# ET6801 register map
Vendor: ETMCU Inc.; File version: v0.0.1
CPU: CM7 r2p1, little endian, MPU, FPU, I-cache, D-cache, ITCM, DTCM, 4 interrupt priority bits
Registers are 32-bit, read-write, reset 0x0 unless marked. A register's access mark holds for its fields unless they carry their own. Offsets are from the block's base; [hi:lo] are bit positions; {n}, {i} and the like mark numbered series.

## SRPWMCOM — Provide an overview of the purpose and functionality of the peripheral: epwmcom_cfg
Base 0x40000000
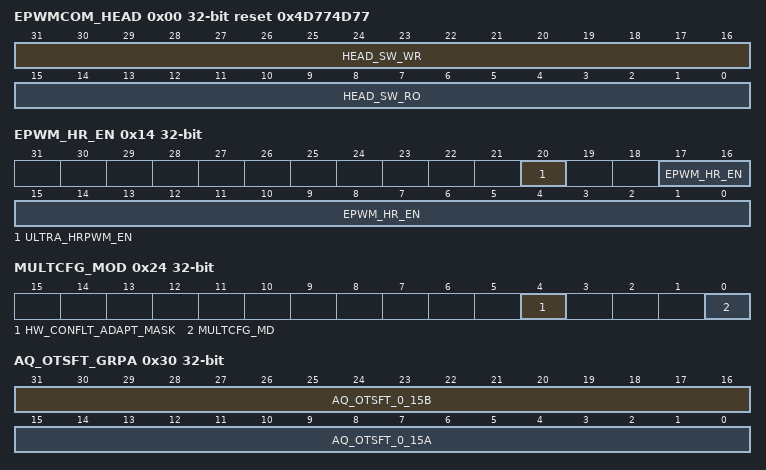
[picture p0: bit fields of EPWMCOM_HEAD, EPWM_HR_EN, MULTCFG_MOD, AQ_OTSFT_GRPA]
0x00 EPWMCOM_HEAD reset 0x4D774D77
  [31:16] HEAD_SW_WR — 软件测试读写寄存器，硬件无访问
  [15:0] HEAD_SW_RO ro — 软件只读上报寄存器，硬件无访问,XXX的ASICII 码表示
0x10 EPWM_EN
  [17:0] EPWM_EN — EPWM模块使能信号，每个EPWM模块对应1bit；bit0~bit11分别对应EPWM0~18； 0：不使能； 1：使能。
0x14 EPWM_HR_EN
  [20] ULTRA_HRPWM_EN — 超高精度PWM模式使能。 'b0：支持分辨率为156.25ps的高精度PWM 'b1：支持分辨率为78.125ps的超高精度PWM
  [17:0] EPWM_HR_EN — EPWM模块高精度发波使能信号，每个EPWM模块对应1bit；bit0~bit11分别对应EPWM0~11； 0：不使能； 1：使能。
0x20 SHD_MULTICFG_UPT
  [17:0] SHD_MULTICFG_UPT — 多个EPWM模块配置寄存器同步更新，写1产生脉冲进行更新；每一bit对应一个epwm模块，bit0~bit18分别对应EPWM0~18；
0x24 MULTCFG_MOD
  [4] HW_CONFLT_ADAPT_MASK — b0：做同步加载的冲突规避 'b1：不做同步加载的冲突规避
  [0] MULTCFG_MD — 同步加载冲突规避模式选择寄存器 1'b0：发生冲突时配置寄存器优先，在软件对参与通道间同步加载的寄存器写配置参数期间，不产生影子加载事件更新活跃值的动作，直至软件完成相关寄存器配置并对寄存器CFG_SHD_MULTICFG_UPT进行写操作后才恢复对影子事件的等待和响应； 1'b1：发生冲突时影子加载事件优先，在影子事件出现之前的一定时间范围内（用户配置时间范围长度），软件写下来的配置不会写到寄存器中。
0x28 MULTCFG_FB_ZONE
  [13:0] MULTCFG_FB_ZONE — 同步加载参数禁止写入区间寄存器，用于指定影子事件出现之前不对（参与通道间同步加载的）寄存器进行更新的时间范围，以SRPWM模块的工作时钟周期为单位，当工作时钟为200MHz时，最大值对应82us左右时间。需注意此寄存器的配置值应小于通道内寄存器CFG_TB_PRD[cfg_tb_prd[28:7]]的配置值。此寄存器配置值仅在CFG_MULT_CFG_MD='b1时才有意义。
0x2C MULTCFG_CONFLICT_RPT ro
  [17:0] MULTCFG_CONFLICT_RPT — 上报同步加载期间的冲突事件。每个比特对应一个PWM通道，LSB对应PWM0通道，MSB对应PWM17通道，高电平表示出现过冲突，置高电平后保持，需要软件通过对寄存器cfg_multcfg_conflict_rpt_clr对应比特写1清除。 当CFG_ MULT_CFG_MD配置为'b0，在某个通道内，从出现第一个同步加载参数的写使能到同步加载指令脉冲（寄存器CFG_SHD_MULTICFG_UPT写1产生的脉冲）出现之前的时间段内如果出现该通道的同步加载影子事件（此时间段内出现的影子事件实际未起作用，未进行活跃值更新），则该通道对应的multcfg_conflict_rpt寄存器比特将被置1。 当CFG_ MULT_CFG_MD配置为'b1，在某个通道内，影子事件出现前的禁止写寄存器时间段内（由寄存器CFG_MULT_CFG_FB_ZONE指定），如果发生软件对同步加载相关寄存器的写操作，则该通道对应的multcfg_conflict_rpt寄存器比特将被置1。
0x30 AQ_OTSFT_GRPA
  [31:16] AQ_OTSFT_0_15B — epwmb信号软件触发一次(one time)强制动作，写1产生脉冲。 bit0~bit11分别对应EPWM0~15； 此寄存器是写自清零寄存器，软件写一次1产生一个脉冲，软件配置1后，对应通道的AQ逻辑响应此脉冲，等到寄存器cfg_aq_sftstart_sync_mselb选定的start事件有效，会执行动作（动作内容由AQ寄存器cfg_aq_ctl_sftb决定），然后等AQ寄存器cfg_aq_sftend_sync_mselb选定的end事件有效，该次软件强制动作结束。由于软件写一次只产生一个脉冲，因此动作持续的时间是从 start事件到end事件的间隔时间。软件配置动作的优先级高于AQ矩阵的其余22个事件。
  [15:0] AQ_OTSFT_0_15A — epwma信号软件触发一次(one time)强制动作，写1产生脉冲。 bit0~bit11分别对应EPWM0~15； 此寄存器是写自清零寄存器，软件写一次1产生一个脉冲，软件配置1后，对应通道的AQ逻辑响应此脉冲，等到寄存器cfg_aq_sftstart_sync_msela选定的start事件有效，会执行动作（动作内容由AQ寄存器cfg_aq_ctl_sfta决定），然后等AQ寄存器cfg_aq_sftend_sync_msela选定的end事件有效，该次软件强制动作结束。由于软件写一次只产生一个脉冲，因此动作持续的时间是从 start事件到end事件的间隔时间。软件配置动作的优先级高于AQ矩阵的其余22个事件。
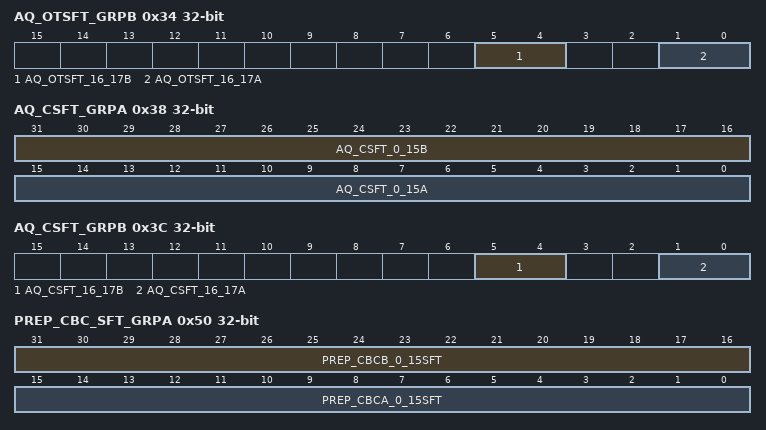
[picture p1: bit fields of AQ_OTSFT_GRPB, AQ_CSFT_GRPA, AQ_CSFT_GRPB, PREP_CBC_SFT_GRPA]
0x34 AQ_OTSFT_GRPB
  [5:4] AQ_OTSFT_16_17B — epwmb信号软件触发一次(one time)强制动作，写1产生脉冲。 bit0~bit1分别对应EPWM16~17； 此寄存器是写自清零寄存器，软件写一次1产生一个脉冲，软件配置1后，对应通道的AQ逻辑响应此脉冲，等到寄存器cfg_aq_sftstart_sync_mselb选定的start事件有效，会执行动作（动作内容由AQ寄存器cfg_aq_ctl_sftb决定），然后等AQ寄存器cfg_aq_sftend_sync_mselb选定的end事件有效，该次软件强制动作结束。由于软件写一次只产生一个脉冲，因此动作持续的时间是从 start事件到end事件的间隔时间。软件配置动作的优先级高于AQ矩阵的其余22个事件。
  [1:0] AQ_OTSFT_16_17A — epwma信号软件触发一次(one time)强制动作，写1产生脉冲。 bit0~bit1分别对应EPWM16~17； 此寄存器是写自清零寄存器，软件写一次1产生一个脉冲，软件配置1后，对应通道的AQ逻辑响应此脉冲，等到寄存器cfg_aq_sftstart_sync_msela选定的start事件有效，会执行动作（动作内容由AQ寄存器cfg_aq_ctl_sfta决定），然后等AQ寄存器cfg_aq_sftend_sync_msela选定的end事件有效，该次软件强制动作结束。由于软件写一次只产生一个脉冲，因此动作持续的时间是从 start事件到end事件的间隔时间。软件配置动作的优先级高于AQ矩阵的其余22个事件。
0x38 AQ_CSFT_GRPA
  [31:16] AQ_CSFT_0_15B — epwmb信号软件持续(continuous)强制动作。配置为1生效，配置0退出。 bit0~bit15分别对应EPWM0~15； 与cfg_aq_otsftb寄存器不同，此寄存器是写1后持续保持高电平，软件配置1后，根据AQ寄存器cfg_aq_sftstart_mdb的配置值不同，会立即产生动作或者是等到寄存器cfg_aq_sftstart_sync_mselb选定的start事件有效再执行动作（动作内容由AQ寄存器cfg_aq_ctl_sftb决定），当前寄存器从置1变为置0后，根据AQ寄存器cfg_aq_sftend_mdb的配置值不同，动作立即结束或等AQ寄存器cfg_aq_sftend_sync_mselb选定的end事件有效，该次软件强制动作结束。软件配置动作的优先级高于AQ矩阵的其余22个事件。
  [15:0] AQ_CSFT_0_15A — epwma信号软件持续(continuous)强制动作。配置为1生效，配置0退出。 bit0~bit15分别对应EPWM0~15； 与cfg_aq_otsfta寄存器不同，此寄存器是写1后持续保持高电平，软件配置1后，根据AQ寄存器cfg_aq_sftstart_mda的配置值不同，会立即产生动作或者是等到寄存器cfg_aq_sftstart_sync_msela选定的start事件有效再执行动作（动作内容由AQ寄存器cfg_aq_ctl_sfta决定），当前寄存器从置1变为置0后，根据AQ寄存器cfg_aq_sftend_mda的配置值不同，动作立即结束或等AQ寄存器cfg_aq_sftend_sync_msela选定的end事件有效，该次软件强制动作结束。软件配置动作的优先级高于AQ矩阵的其余22个事件。
0x3C AQ_CSFT_GRPB
  [5:4] AQ_CSFT_16_17B — epwmb信号软件持续(continuous)强制动作。配置为1生效，配置0退出。 bit0~bit1分别对应EPWM16~17； 与cfg_aq_otsftb寄存器不同，此寄存器是写1后持续保持高电平，软件配置1后，根据AQ寄存器cfg_aq_sftstart_mdb的配置值不同，会立即产生动作或者是等到寄存器cfg_aq_sftstart_sync_mselb选定的start事件有效再执行动作（动作内容由AQ寄存器cfg_aq_ctl_sftb决定），当前寄存器从置1变为置0后，根据AQ寄存器cfg_aq_sftend_mdb的配置值不同，动作立即结束或等AQ寄存器cfg_aq_sftend_sync_mselb选定的end事件有效，该次软件强制动作结束。软件配置动作的优先级高于AQ矩阵的其余22个事件。
  [1:0] AQ_CSFT_16_17A — epwma信号软件持续(continuous)强制动作。配置为1生效，配置0退出。 bit0~bit1分别对应EPWM16~17； 与cfg_aq_otsfta寄存器不同，此寄存器是写1后持续保持高电平，软件配置1后，根据AQ寄存器cfg_aq_sftstart_mda的配置值不同，会立即产生动作或者是等到寄存器cfg_aq_sftstart_sync_msela选定的start事件有效再执行动作（动作内容由AQ寄存器cfg_aq_ctl_sfta决定），当前寄存器从置1变为置0后，根据AQ寄存器cfg_aq_sftend_mda的配置值不同，动作立即结束或等AQ寄存器cfg_aq_sftend_sync_msela选定的end事件有效，该次软件强制动作结束。软件配置动作的优先级高于AQ矩阵的其余22个事件。
0x40 EPWM_SFT_EVT
  [17:0] EPWM_SFT_EVT — 软件事件，通过软件写1产生脉冲，得到对应的事件；用于各种同步信号选择； bit0~bit17分别对应EPWM0~17；
0x44 MULTCFG_CONFLT_CLR
  [17:0] MULTCFG_CONFLICT_RPT_CLR — 软件事件，通过软件写1产生脉冲，得到对应的事件；用于一一对应清除cfg_multcfg_conflict_rpt寄存器； bit0~bit17分别对应EPWM0~17；
0x50 PREP_CBC_SFT_GRPA
  [31:16] PREP_CBCB_0_15SFT — 软件配置触发epwmb产生CBC保护，写1产生脉冲。 bit0~bit15分别对应EPWM0~15；
  [15:0] PREP_CBCA_0_15SFT — 软件配置触发epwma产生CBC保护，写1产生脉冲。 bit0~bit15分别对应EPWM0~15；
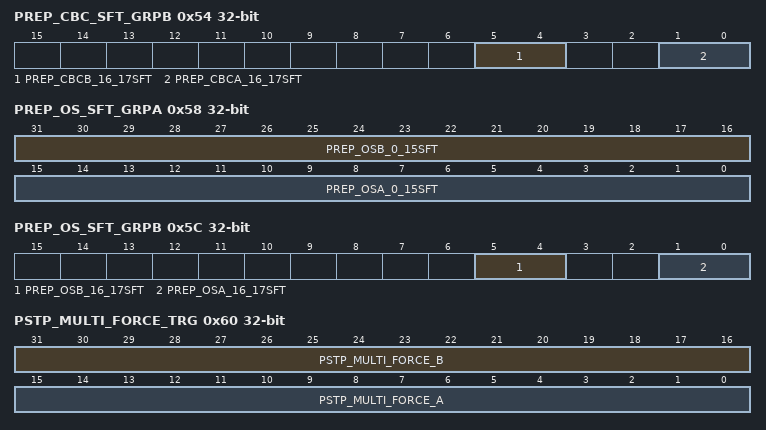
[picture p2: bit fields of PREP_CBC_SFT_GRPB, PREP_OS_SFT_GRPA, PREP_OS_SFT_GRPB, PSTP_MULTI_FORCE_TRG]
0x54 PREP_CBC_SFT_GRPB
  [5:4] PREP_CBCB_16_17SFT — 软件配置触发epwmb产生CBC保护，写1产生脉冲。 bit0~bit1分别对应EPWM16~17；
  [1:0] PREP_CBCA_16_17SFT — 软件配置触发epwma产生CBC保护，写1产生脉冲。 bit0~bit1分别对应EPWM16~17；
0x58 PREP_OS_SFT_GRPA
  [31:16] PREP_OSB_0_15SFT — 软件配置触发epwmb产生one shot保护，软件配置产生电平。 bit0~bit11分别对应EPWM0~11；
  [15:0] PREP_OSA_0_15SFT — 软件配置触发epwma产生one shot保护，软件配置产生电平。 bit0~bit11分别对应EPWM0~11；
0x5C PREP_OS_SFT_GRPB
  [5:4] PREP_OSB_16_17SFT — 软件配置触发epwmb产生one shot保护，软件配置产生电平。 bit0~bit1分别对应EPWM16~17；
  [1:0] PREP_OSA_16_17SFT — 软件配置触发epwma产生one shot保护，软件配置产生电平。 bit0~bit1分别对应EPWM16~17；
0x60 PSTP_MULTI_FORCE_TRG
  [31:16] PSTP_MULTI_FORCE_B — 写1产生触发脉冲，软件配置触发pwmb产生强制次级保护动作， bit0~bit15分别对应SRPWMB0~15。此触发动作仅在通道内寄存器CFG_PSTP_SFT_FORCE[cfg_pstp_glb_force_en]='b1时有效（每个PWM通道独立配置），具体强制动作结果由通道内寄存器CFG_PSTP_SFT_FORCE配置。
  [15:0] PSTP_MULTI_FORCE_A — 写1产生触发脉冲，软件配置触发pwma产生强制次级保护动作， bit0~bit15分别对应SRPWMA0~15。此触发动作仅在通道内寄存器CFG_PSTP_SFT_FORCE[cfg_pstp_glb_force_en]='b1时有效（每个PWM通道独立配置），具体强制动作结果由通道内寄存器CFG_PSTP_SFT_FORCE配置。
0x64 PSTP_MCHAN_FORCE_TRG
  [17:0] PSTP_MCHAN_FORCE_TRG — 写1产生触发脉冲，软件配置触发pwm通道的a、b支路产生强制次级保护动作， bit0~bit17分别对应SRPWM0~17。此触发动作仅在通道内寄存器CFG_PSTP_SFT_FORCE[cfg_pstp_glb_force_en]='b1时有效（每个PWM通道独立配置），具体强制动作结果由通道内寄存器CFG_PSTP_SFT_FORCE配置。
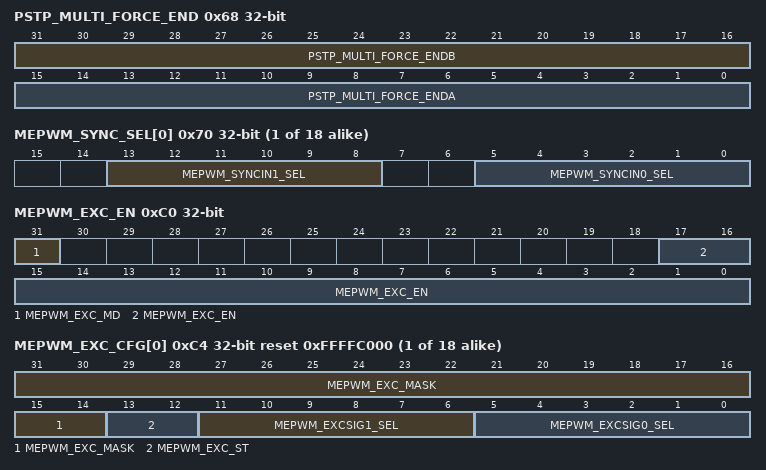
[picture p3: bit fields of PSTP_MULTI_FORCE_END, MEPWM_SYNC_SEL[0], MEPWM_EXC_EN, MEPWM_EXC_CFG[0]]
0x68 PSTP_MULTI_FORCE_END
  [31:16] PSTP_MULTI_FORCE_ENDB — 写1产生触发脉冲，软件配置pwmb停止公共寄存器CFG_PSTP_MULTI_FORCE_TRG[cfg_pstp_multi_force_b]触发的次级保护动作，直至cfg_pstp_multi_force_b 或cfg_pstp_mchan_force再次写'b1产生下一次强制动作。bit0~bit15分别对应SRPWMB0~15。此停止动作仅在通道内寄存器CFG_PSTP_SFT_FORCE[cfg_pstp_glb_force_en]='b1时有效（每个PWM通道独立配置）。
  [15:0] PSTP_MULTI_FORCE_ENDA — 写1产生触发脉冲，软件配置pwma停止公共寄存器cfg_pstp_multi_force_a或cfg_pstp_mchan_force触发的次级保护动作，直至cfg_pstp_multi_force_a 或cfg_pstp_mchan_force再次写'b1产生下一次强制动作。bit0~bit15分别对应SRPWMA0~15。此停止动作仅在通道内寄存器CFG_PSTP_SFT_FORCE[cfg_pstp_glb_force_en]='b1时有效（每个PWM通道独立配置）。
0x6C PSTP_MCHAN_FORCE_END
  [17:0] PSTP_MCHAN_FORCE_END — 写1产生触发脉冲，软件配置pwm通道的a、b支路均停止公共寄存器cfg_pstp_multi_force_a/b或cfg_pstp_mchan_force触发的次级保护动作，直至cfg_pstp_multi_force_a/b或cfg_pstp_mchan_force 再次写'b1产生下一次强制动作。bit0~bit15分别对应SRPWMA0~15。此停止动作仅在通道内寄存器CFG_PSTP_SFT_FORCE[cfg_pstp_glb_force_en]='b1时有效（每个PWM通道独立配置）。
{0x70+4i} MEPWM_SYNC_SEL[{i}] (i=0..17) — MEPWM_SYNC_SEL%S
  [13:8] MEPWM_SYNCIN1_SEL — EPWM模块输入同步信号1选择； 0,2,4....34分别对应选择epwm0~18的syncout0； 1,3,5....35分别对应选择epwm0~18的syncout1；
  [5:0] MEPWM_SYNCIN0_SEL — EPWM模块输入同步信号0选择； 0,2,4....34分别对应选择epwm0~18的syncout0； 1,3,5....35分别对应选择epwm0~18的syncout1；
0xC0 MEPWM_EXC_EN
  [31] MEPWM_EXC_MD — EPWM间的pwm信号互斥判断工作模式； 0：互斥条件成立，互斥保护立即生效，互斥条件消失，互斥保护立即撤销； 1：互斥条件成立，互斥保护立即生效，且互斥状态锁存，互斥条件消失，互斥保护仍存在，直至cfg_mepwm_exc_clr清除互斥状态；
  [17:0] MEPWM_EXC_EN — EPWM间的pwm信号互斥判断使能配置； 0：不互斥判断； 1：互斥判断。
{0xC4+4i} MEPWM_EXC_CFG[{i}] (i=0..17) reset 0xFFFFC000 — MEPWM_EXC_CFG%S
  [31:14] MEPWM_EXC_MASK — 产生的互斥指示是否作用与该epwm模块的屏蔽配置； 0：表示不屏蔽该指示； 1：表示屏蔽该指示。
  [13:12] MEPWM_EXC_ST — 选择后的两个互斥信号的互斥状态配置。 00：a和b同时为低产生互斥； 01：a为低，b为高产生互斥； 10：a为高，b为低产生互斥； 11：a和b同时为高产生互斥。
  [11:6] MEPWM_EXCSIG1_SEL — EPWM间的pwm互斥信号1选择。 0~17分别对应选择epwm0~17的pwma； 18~35 分别对应选择epwm0~17的pwmb；
  [5:0] MEPWM_EXCSIG0_SEL — EPWM间的pwm互斥信号0选择。 0~17分别对应选择epwm0~18的pwma； 18~35 分别对应选择epwm0~18的pwmb；
0x110 MEPWM_EXC_CLR
  [17:0] MEPWM_EXC_CLR — EPWM间的pwm信号互斥指示清零配置；写1产生脉冲；
0x114 MEPWM_EXC_RPT ro
  [17:0] MEPWM_EXC_FLG_RPT — EPWM间的pwm信号互斥指示上报
0x130 MEPWM_DMA_EN
  [17:0] MEPWM_DMA_EN — MEPWM DMA请求信号使能； 0：不使能； 1：使能。 bit0~17分别对应epwm0~17的DMA请求
0x140 MEPWM_TBCNT_LC_EN
  [2:0] MEPWM_TBCNT_LC_EN — epwm time计数器锁存使能。 0：不使能； 1：使能。 bit0：对应使能epwm0~5的timer计数值锁存； bit1：对应使能epwm6~11的timer计数值锁存； bit2：对应使能epwm12~17的timer计数值锁存；
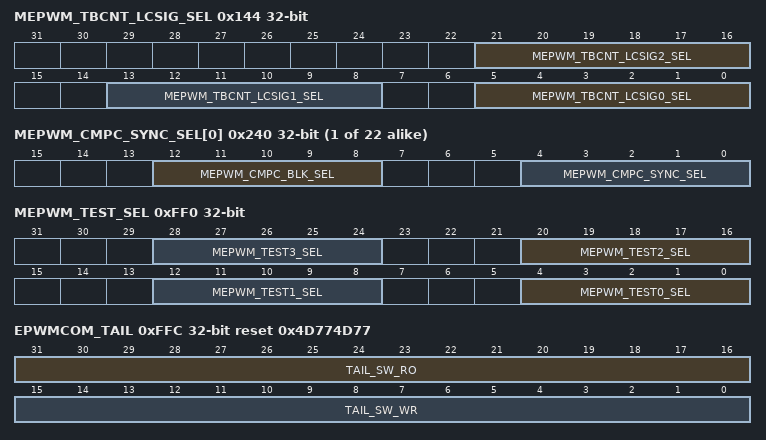
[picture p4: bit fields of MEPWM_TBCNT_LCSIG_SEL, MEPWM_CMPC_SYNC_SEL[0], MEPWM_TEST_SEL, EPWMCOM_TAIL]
0x144 MEPWM_TBCNT_LCSIG_SEL
  [21:16] MEPWM_TBCNT_LCSIG2_SEL — EPWM timer计数器锁存同步信号2选择； 0,2,4....34分别对应选择epwm0~11的syncout0； 1,3,5....35分别对应选择epwm0~11的syncout1； 36 选择cfg_mepwm_tbcnt_lc_en[2]上升沿； 同步信号2用于锁存epmw12~17的timer计数。
  [13:8] MEPWM_TBCNT_LCSIG1_SEL — EPWM timer计数器锁存同步信号1选择； 0,2,4....34分别对应选择epwm0~11的syncout0； 1,3,5....35分别对应选择epwm0~11的syncout1； 36 选择cfg_mepwm_tbcnt_lc_en[1]上升沿； 同步信号1用于锁存epmw6~11的timer计数。
  [5:0] MEPWM_TBCNT_LCSIG0_SEL — EPWM timer计数器锁存同步信号0选择； 0,2,4....34分别对应选择epwm0~11的syncout0； 1,3,5....35分别对应选择epwm0~11的syncout1； 36 选择cfg_mepwm_tbcnt_lc_en[0]上升沿； 同步信号0用于锁存epmw0~5的timer计数。
{0x150+4i} TB_SFTLOCK[{i}] (i=0..17) ro — TB_SFTLOCK%S
  [21:0] EPWM_TBCNT_LC_RPT — epwm的timer 计数值锁存上报。
{0x200+4i} MEPWM_XBAR_SYNC_SEL[{i}] (i=0..3) — MEPWM_XBAR_SYNC_SEL%S
  [5:0] MEPWM_XBAR_SYNC_SEL — 输出给XBAR的同步信号选择 0,2,4....34分别对应选择epwm0~11输出的epwm_syncout0； 1,3,5...35 分别对应选择epwm0~11输出的epwm_syncout1；
{0x220+4i} MEPWM_DACC_SYNC_SEL[{i}] (i=0..1) — MEPWM_DACC_SYNC_SEL%S
  [4:0] MEPWM_DACC_SYNC_SEL — 从18个通道共18比特的BDAC sync信号中选择一个sync，输出给BDAC的控制模块DACC作为同步信号 'd0：选择通道0的BDAC sync信号； ...... d'17：选择通道17的BDAC sync信号； others：无sync信号输出，输出保持为0值。
{0x240+4i} MEPWM_CMPC_SYNC_SEL[{i}] (i=0..21) — MEPWM_CMPC_SYNC_SEL%S
  [12:8] MEPWM_CMPC_BLK_SEL — 从18个通道共18比特的CMPC blk信号中选择一个blk触发，输出给模拟比较器的控制模块CMPC作为产生消隐的触发信号： 'd0：选择通道0的CMPC blk信号； ...... d'17：选择通道11的CMPC blk信号； others：无blk信号输出，输出保持为0值。
  [4:0] MEPWM_CMPC_SYNC_SEL — 从18个通道共18比特的CMPC sync信号中选择一个sync，输出给模拟比较器的控制模块CMPC作为同步信号 'd0：选择通道0的CMPC sync信号； ...... d'17：选择通道11的CMPC sync信号； others：无sync信号输出，输出保持为0值。
{0x2A0+4i} MEPWM_QEP_SYNC_SEL[{i}] (i=0..1) — MEPWM_QEP_SYNC_SEL%S
  [17:0] MEPWM_QEP_SYNC_MSEL — 从epwm0~17输出的ADC触发信号中选择出若干个比特做或运算后送到QEP。 bit0：对应选择epwm0_sadcx_trig； bit1：对应选择epwm1_sadcx_trig； ...... bit17：对应选择epwm17_sadcx_trig。 sadcx中x=0，1，地址0x2a0对应x=0,0x2a4对应x=1
0xEF0 SOFT_CLR_TB
  [17:0] SFT_TBCNT_CLR — 18个PWM通道内部的timer base清除配置； [0]:清除PWM0通道timerbase内部计数值及计数方向； [1]:清除PWM1通道timerbase内部计数值及计数方向； [2]:清除PWM2通道timerbase内部计数值及计数方向； ...... [17]:清除PWM17通道timerbase内部计数值及计数方向；
0xFF0 MEPWM_TEST_SEL
  [8n+4:8n] MEPWM_TEST{n}_SEL (n=0..3) — TEST{n} 信号选择
0xFFC EPWMCOM_TAIL reset 0x4D774D77
  [31:16] TAIL_SW_RO ro — 软件只读硬件上报寄存器
  [15:0] TAIL_SW_WR — 软件测试读写寄存器，硬件无访问
